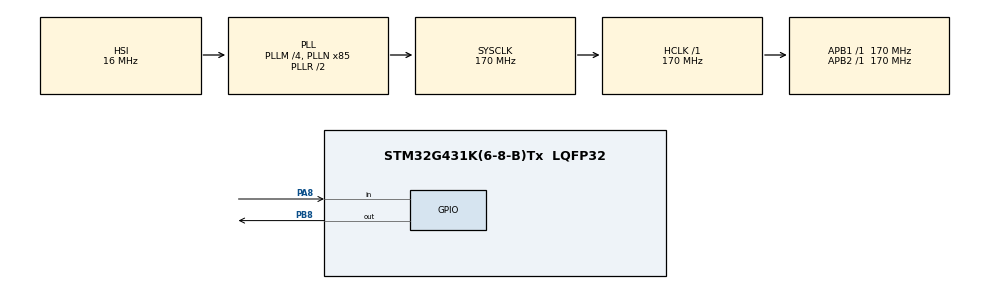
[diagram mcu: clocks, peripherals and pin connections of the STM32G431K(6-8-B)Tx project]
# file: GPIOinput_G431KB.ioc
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Mcu.Family=STM32G4
Mcu.Name=STM32G431K(6-8-B)Tx
Mcu.Package=LQFP32
NUCLEO-G431KB.LD2=true
NUCLEO-G431KB.VCP=true
NVIC.PriorityGroup=NVIC_PRIORITYGROUP_4
PA13.GPIO_Label=T_SWDIO
PA13.Signal=SYS_JTMS-SWDIO
PA14.GPIO_Label=T_SWCLK
PA14.Signal=SYS_JTCK-SWCLK
PA2.Signal=USART2_TX
PA3.Signal=USART2_RX
PA8.GPIO_PuPd=GPIO_PULLDOWN
PA8.Signal=GPIO_Input
PB3.GPIO_Label=T_SWO
PB3.Signal=SYS_JTDO-SWO
PB8-BOOT0.Signal=GPIO_Output
ProjectManager.HeapSize=0x200
ProjectManager.StackSize=0x400
ProjectManager.TargetToolchain=CMake
RCC.ADC12Freq_Value=170000000
RCC.AHBFreq_Value=170000000
RCC.APB1Freq_Value=170000000
RCC.APB1TimFreq_Value=170000000
RCC.APB2Freq_Value=170000000
RCC.APB2TimFreq_Value=170000000
RCC.CortexFreq_Value=170000000
RCC.EXTERNAL_CLOCK_VALUE=12288000
RCC.HCLKFreq_Value=170000000
RCC.HSE_VALUE=8000000
RCC.HSI48_VALUE=48000000
RCC.HSI_VALUE=16000000
RCC.LSE_VALUE=32768
RCC.PLLM=RCC_PLLM_DIV4
RCC.PLLN=85
RCC.SYSCLKFreq_VALUE=170000000
RCC.SYSCLKSource=RCC_SYSCLKSOURCE_PLLCLK
RCC.USBFreq_Value=170000000
RCC.VCOOutputFreq_Value=340000000
VP_NUCLEO-G431KB_VS_BSP_COMMON.Mode=COMMON
board=NUCLEO-G431KB

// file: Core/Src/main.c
/* USER CODE BEGIN Header */
/**
 ******************************************************************************
 * @file           : main.c
 * @brief          : Main program body
 ******************************************************************************
 * @attention
 *
 * Copyright (c) 2025 STMicroelectronics.
 * All rights reserved.
 *
 * This software is licensed under terms that can be found in the LICENSE file
 * in the root directory of this software component.
 * If no LICENSE file comes with this software, it is provided AS-IS.
 *
 ******************************************************************************
 */
/* USER CODE END Header */
#include "main.h"

COM_InitTypeDef BspCOMInit;

void SystemClock_Config(void);
static void MX_GPIO_Init(void);

int main(void)
{

  /* MCU Configuration--------------------------------------------------------*/

  /* Reset of all peripherals, Initializes the Flash interface and the Systick. */
  HAL_Init();

  /* Configure the system clock */
  SystemClock_Config();

  /* Initialize all configured peripherals */
  MX_GPIO_Init();

  /* Initialize leds */
  BSP_LED_Init(LED_GREEN);

  /* Initialize COM1 port (115200, 8 bits (7-bit data + 1 stop bit), no parity */
  BspCOMInit.BaudRate   = 115200;
  BspCOMInit.WordLength = COM_WORDLENGTH_8B;
  BspCOMInit.StopBits   = COM_STOPBITS_1;
  BspCOMInit.Parity     = COM_PARITY_NONE;
  BspCOMInit.HwFlowCtl  = COM_HWCONTROL_NONE;
  if (BSP_COM_Init(COM1, &BspCOMInit) != BSP_ERROR_NONE)
  {
    Error_Handler();
  }

  /* Infinite loop */
  while (1) {

    /* USER CODE BEGIN 3 */
    GPIO_PinState state = HAL_GPIO_ReadPin(GPIOA, GPIO_PIN_8);
    if (state == GPIO_PIN_SET) {
      HAL_GPIO_WritePin(GPIOB, GPIO_PIN_8, GPIO_PIN_SET);
    } else {
      HAL_GPIO_WritePin(GPIOB, GPIO_PIN_8, GPIO_PIN_RESET);
    }
  }
  /* USER CODE END 3 */
}

void SystemClock_Config(void)
{
  RCC_OscInitTypeDef RCC_OscInitStruct = {0};
  RCC_ClkInitTypeDef RCC_ClkInitStruct = {0};

  /** Configure the main internal regulator output voltage
  */
  HAL_PWREx_ControlVoltageScaling(PWR_REGULATOR_VOLTAGE_SCALE1_BOOST);

  /** Initializes the RCC Oscillators according to the specified parameters
  * in the RCC_OscInitTypeDef structure.
  */
  RCC_OscInitStruct.OscillatorType = RCC_OSCILLATORTYPE_HSI;
  RCC_OscInitStruct.HSIState = RCC_HSI_ON;
  RCC_OscInitStruct.HSICalibrationValue = RCC_HSICALIBRATION_DEFAULT;
  RCC_OscInitStruct.PLL.PLLState = RCC_PLL_ON;
  RCC_OscInitStruct.PLL.PLLSource = RCC_PLLSOURCE_HSI;
  RCC_OscInitStruct.PLL.PLLM = RCC_PLLM_DIV4;
  RCC_OscInitStruct.PLL.PLLN = 85;
  RCC_OscInitStruct.PLL.PLLP = RCC_PLLP_DIV2;
  RCC_OscInitStruct.PLL.PLLQ = RCC_PLLQ_DIV2;
  RCC_OscInitStruct.PLL.PLLR = RCC_PLLR_DIV2;
  if (HAL_RCC_OscConfig(&RCC_OscInitStruct) != HAL_OK)
  {
    Error_Handler();
  }

  /** Initializes the CPU, AHB and APB buses clocks
  */
  RCC_ClkInitStruct.ClockType = RCC_CLOCKTYPE_HCLK|RCC_CLOCKTYPE_SYSCLK
                              |RCC_CLOCKTYPE_PCLK1|RCC_CLOCKTYPE_PCLK2;
  RCC_ClkInitStruct.SYSCLKSource = RCC_SYSCLKSOURCE_PLLCLK;
  RCC_ClkInitStruct.AHBCLKDivider = RCC_SYSCLK_DIV1;
  RCC_ClkInitStruct.APB1CLKDivider = RCC_HCLK_DIV1;
  RCC_ClkInitStruct.APB2CLKDivider = RCC_HCLK_DIV1;

  if (HAL_RCC_ClockConfig(&RCC_ClkInitStruct, FLASH_LATENCY_4) != HAL_OK)
  {
    Error_Handler();
  }
}

static void MX_GPIO_Init(void)
{
  GPIO_InitTypeDef GPIO_InitStruct = {0};

  /* GPIO Ports Clock Enable */
  __HAL_RCC_GPIOA_CLK_ENABLE();
  __HAL_RCC_GPIOB_CLK_ENABLE();

  /*Configure GPIO pin Output Level */
  HAL_GPIO_WritePin(GPIOB, GPIO_PIN_8, GPIO_PIN_RESET);

  /*Configure GPIO pin : PA8 */
  GPIO_InitStruct.Pin = GPIO_PIN_8;
  GPIO_InitStruct.Mode = GPIO_MODE_INPUT;
  GPIO_InitStruct.Pull = GPIO_PULLDOWN;
  HAL_GPIO_Init(GPIOA, &GPIO_InitStruct);

  /*Configure GPIO pin : PB8 */
  GPIO_InitStruct.Pin = GPIO_PIN_8;
  GPIO_InitStruct.Mode = GPIO_MODE_OUTPUT_PP;
  GPIO_InitStruct.Pull = GPIO_NOPULL;
  GPIO_InitStruct.Speed = GPIO_SPEED_FREQ_LOW;
  HAL_GPIO_Init(GPIOB, &GPIO_InitStruct);

}

/* USER CODE BEGIN Header */
/**
 ******************************************************************************
 * @file           : main.c
 * @brief          : Main program body
 ******************************************************************************
 * @attention
 *
 * Copyright (c) 2025 STMicroelectronics.
 * All rights reserved.
 *
 * This software is licensed under terms that can be found in the LICENSE file
 * in the root directory of this software component.
 * If no LICENSE file comes with this software, it is provided AS-IS.
 *
 ******************************************************************************
 */
/* USER CODE END Header */

void Error_Handler(void)
{
  __disable_irq();
  while (1) {
  }
}

#ifdef  USE_FULL_ASSERT
/**
  * @brief  Reports the name of the source file and the source line number
  *         where the assert_param error has occurred.
  * @param  file: pointer to the source file name
  * @param  line: assert_param error line source number
  * @retval None
  */
void assert_failed(uint8_t *file, uint32_t line)
{
  /* USER CODE BEGIN 6 */
  /* User can add his own implementation to report the file name and line
     number, ex: printf("Wrong parameters value: file %s on line %d\r\n", file,
     line) */
  /* USER CODE END 6 */
}
#endif /* USE_FULL_ASSERT */
